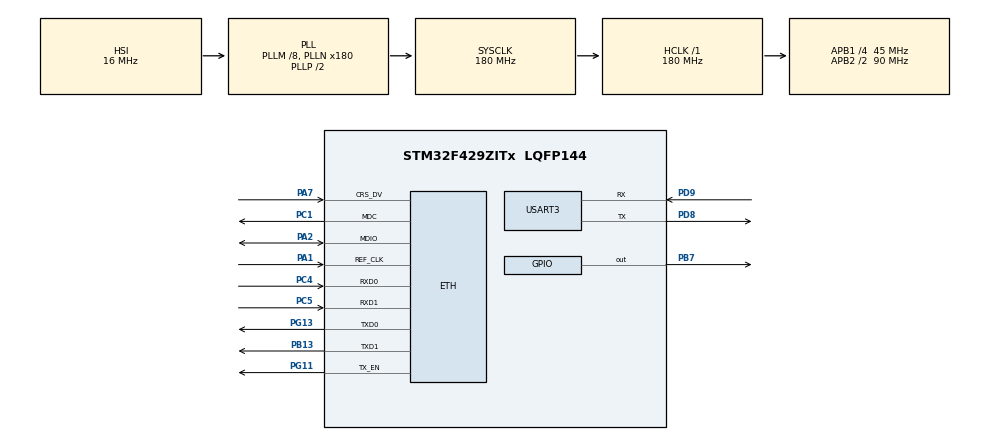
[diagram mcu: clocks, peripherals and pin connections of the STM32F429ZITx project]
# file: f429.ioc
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ETH.MediaInterface=HAL_ETH_RMII_MODE
FREERTOS.Tasks01=defaultTask,0,1024,StartDefaultTask,Default,NULL,Dynamic,NULL,NULL
FREERTOS.configTOTAL_HEAP_SIZE=131072
FREERTOS.configUSE_NEWLIB_REENTRANT=1
LWIP.BSP.number=1
LWIP.DHCP_DEBUG=LWIP_DBG_OFF
LWIP.LWIP_HTTPD=1
LWIP.LWIP_HTTPD_DYNAMIC_HEADERS=1
LWIP.LWIP_HTTPD_SSI_BY_FILE_EXTENSION=0
LWIP.LWIP_NETIF_STATUS_CALLBACK=1
LWIP.MEMP_NUM_PBUF=32
LWIP.MEMP_NUM_RAW_PCB=8
LWIP.MEMP_NUM_TCP_PCB=10
LWIP.MEM_SIZE=16384
LWIP.PBUF_POOL_SIZE=32
LWIP.Version=v2.1.2_Cube
LWIP0.BSP.STBoard=false
LWIP0.BSP.api=BSP_COMPONENT_DRIVER
LWIP0.BSP.component=LAN8742
LWIP0.BSP.instance=LAN8742
LWIP0.BSP.name=Driver_PHY
LWIP0.BSP.semaphore=S_LAN8742
LWIP0.BSP.solution=LAN8742
Mcu.Family=STM32F4
Mcu.Name=STM32F429ZITx
Mcu.Package=LQFP144
NVIC.ETH_IRQn=true\:5\:0\:false\:false\:true\:true\:true\:true\:true
NVIC.PriorityGroup=NVIC_PRIORITYGROUP_4
PA1.Mode=RMII
PA1.Signal=ETH_REF_CLK
PA2.Mode=RMII
PA2.Signal=ETH_MDIO
PA7.Mode=RMII
PA7.Signal=ETH_CRS_DV
PB13.Mode=RMII
PB13.Signal=ETH_TXD1
PB7.Signal=GPIO_Output
PC1.Mode=RMII
PC1.Signal=ETH_MDC
PC4.Mode=RMII
PC4.Signal=ETH_RXD0
PC5.Mode=RMII
PC5.Signal=ETH_RXD1
PD8.Mode=Asynchronous
PD8.Signal=USART3_TX
PD9.Mode=Asynchronous
PD9.Signal=USART3_RX
PG11.Mode=RMII
PG11.Signal=ETH_TX_EN
PG13.Mode=RMII
PG13.Signal=ETH_TXD0
ProjectManager.HeapSize=0x200
ProjectManager.StackSize=0x400
ProjectManager.TargetToolchain=STM32CubeIDE
RCC.48MHZClocksFreq_Value=90000000
RCC.AHBFreq_Value=180000000
RCC.APB1CLKDivider=RCC_HCLK_DIV4
RCC.APB1Freq_Value=45000000
RCC.APB1TimFreq_Value=90000000
RCC.APB2CLKDivider=RCC_HCLK_DIV2
RCC.APB2Freq_Value=90000000
RCC.APB2TimFreq_Value=180000000
RCC.CortexFreq_Value=180000000
RCC.HCLKFreq_Value=180000000
RCC.HSE_VALUE=25000000
RCC.HSI_VALUE=16000000
RCC.LSE_VALUE=32768
RCC.PLLM=8
RCC.PLLN=180
RCC.SYSCLKFreq_VALUE=180000000
RCC.SYSCLKSource=RCC_SYSCLKSOURCE_PLLCLK
RCC.VCOOutputFreq_Value=360000000
USART3.VirtualMode=VM_ASYNC
VP_FREERTOS_VS_CMSIS_V1.Mode=CMSIS_V1
VP_LWIP_VS_Enabled.Mode=Enabled
board=custom

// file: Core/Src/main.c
/* USER CODE BEGIN Header */
/**
  ******************************************************************************
  * @file           : main.c
  * @brief          : Main program body
  ******************************************************************************
  * @attention
  *
  * Copyright (c) 2022 STMicroelectronics.
  * All rights reserved.
  *
  * This software is licensed under terms that can be found in the LICENSE file
  * in the root directory of this software component.
  * If no LICENSE file comes with this software, it is provided AS-IS.
  *
  ******************************************************************************
  */
/* USER CODE END Header */
#include "main.h"
#include "cmsis_os.h"
#include "lwip.h"

UART_HandleTypeDef huart3;

osThreadId defaultTaskHandle;

void SystemClock_Config(void);
static void MX_GPIO_Init(void);
static void MX_USART3_UART_Init(void);
void StartDefaultTask(void const * argument);

int main(void)
{

  /* MCU Configuration--------------------------------------------------------*/

  /* Reset of all peripherals, Initializes the Flash interface and the Systick. */
  HAL_Init();

  /* Configure the system clock */
  SystemClock_Config();

  /* Initialize all configured peripherals */
  MX_GPIO_Init();
  MX_USART3_UART_Init();
  /* USER CODE BEGIN 2 */
//  for(;;) { HAL_Delay(250); HAL_GPIO_TogglePin(GPIOB, GPIO_PIN_7); }
  /* USER CODE END 2 */

  /* Create the thread(s) */
  /* definition and creation of defaultTask */
  osThreadDef(defaultTask, StartDefaultTask, osPriorityNormal, 0, 1024);
  defaultTaskHandle = osThreadCreate(osThread(defaultTask), NULL);

  /* Start scheduler */
  osKernelStart();

  /* We should never get here as control is now taken by the scheduler */
  /* Infinite loop */
  while (1)
  {

  }
}

void SystemClock_Config(void)
{
  RCC_OscInitTypeDef RCC_OscInitStruct = {0};
  RCC_ClkInitTypeDef RCC_ClkInitStruct = {0};

  /** Configure the main internal regulator output voltage
  */
  __HAL_RCC_PWR_CLK_ENABLE();
  __HAL_PWR_VOLTAGESCALING_CONFIG(PWR_REGULATOR_VOLTAGE_SCALE1);

  /** Initializes the RCC Oscillators according to the specified parameters
  * in the RCC_OscInitTypeDef structure.
  */
  RCC_OscInitStruct.OscillatorType = RCC_OSCILLATORTYPE_HSI;
  RCC_OscInitStruct.HSIState = RCC_HSI_ON;
  RCC_OscInitStruct.HSICalibrationValue = RCC_HSICALIBRATION_DEFAULT;
  RCC_OscInitStruct.PLL.PLLState = RCC_PLL_ON;
  RCC_OscInitStruct.PLL.PLLSource = RCC_PLLSOURCE_HSI;
  RCC_OscInitStruct.PLL.PLLM = 8;
  RCC_OscInitStruct.PLL.PLLN = 180;
  RCC_OscInitStruct.PLL.PLLP = RCC_PLLP_DIV2;
  RCC_OscInitStruct.PLL.PLLQ = 4;
  if (HAL_RCC_OscConfig(&RCC_OscInitStruct) != HAL_OK)
  {
    Error_Handler();
  }

  /** Activate the Over-Drive mode
  */
  if (HAL_PWREx_EnableOverDrive() != HAL_OK)
  {
    Error_Handler();
  }

  /** Initializes the CPU, AHB and APB buses clocks
  */
  RCC_ClkInitStruct.ClockType = RCC_CLOCKTYPE_HCLK|RCC_CLOCKTYPE_SYSCLK
                              |RCC_CLOCKTYPE_PCLK1|RCC_CLOCKTYPE_PCLK2;
  RCC_ClkInitStruct.SYSCLKSource = RCC_SYSCLKSOURCE_PLLCLK;
  RCC_ClkInitStruct.AHBCLKDivider = RCC_SYSCLK_DIV1;
  RCC_ClkInitStruct.APB1CLKDivider = RCC_HCLK_DIV4;
  RCC_ClkInitStruct.APB2CLKDivider = RCC_HCLK_DIV2;

  if (HAL_RCC_ClockConfig(&RCC_ClkInitStruct, FLASH_LATENCY_5) != HAL_OK)
  {
    Error_Handler();
  }
}

static void MX_USART3_UART_Init(void)
{

  huart3.Instance = USART3;
  huart3.Init.BaudRate = 115200;
  huart3.Init.WordLength = UART_WORDLENGTH_8B;
  huart3.Init.StopBits = UART_STOPBITS_1;
  huart3.Init.Parity = UART_PARITY_NONE;
  huart3.Init.Mode = UART_MODE_TX_RX;
  huart3.Init.HwFlowCtl = UART_HWCONTROL_NONE;
  huart3.Init.OverSampling = UART_OVERSAMPLING_16;
  if (HAL_UART_Init(&huart3) != HAL_OK)
  {
    Error_Handler();
  }

}

static void MX_GPIO_Init(void)
{
  GPIO_InitTypeDef GPIO_InitStruct = {0};

  /* GPIO Ports Clock Enable */
  __HAL_RCC_GPIOC_CLK_ENABLE();
  __HAL_RCC_GPIOA_CLK_ENABLE();
  __HAL_RCC_GPIOB_CLK_ENABLE();
  __HAL_RCC_GPIOD_CLK_ENABLE();
  __HAL_RCC_GPIOG_CLK_ENABLE();

  /*Configure GPIO pin Output Level */
  HAL_GPIO_WritePin(GPIOB, GPIO_PIN_7, GPIO_PIN_RESET);

  /*Configure GPIO pin : PB7 */
  GPIO_InitStruct.Pin = GPIO_PIN_7;
  GPIO_InitStruct.Mode = GPIO_MODE_OUTPUT_PP;
  GPIO_InitStruct.Pull = GPIO_NOPULL;
  GPIO_InitStruct.Speed = GPIO_SPEED_FREQ_LOW;
  HAL_GPIO_Init(GPIOB, &GPIO_InitStruct);

}

/* USER CODE BEGIN 4 */
int ip_ready = 0;
/* USER CODE END 4 */

void StartDefaultTask(void const * argument)
{
  /* init code for LWIP */
  MX_LWIP_Init();
  /* USER CODE BEGIN 5 */
  /* Infinite loop */
  extern struct netif gnetif;
  extern void httpd_init(void);
  while (gnetif.ip_addr.addr == 0) HAL_Delay(100);
  httpd_init();

  for(;;) {
	  HAL_Delay(1250); HAL_GPIO_TogglePin(GPIOB, GPIO_PIN_7);
    printf("hi, time %lu, ram: %lu, lwm: %lu\r\n", HAL_GetTick(),
          xPortGetFreeHeapSize(),
          xPortGetMinimumEverFreeHeapSize());
  }
  /* USER CODE END 5 */
}

void Error_Handler(void)
{
  __disable_irq();
  while (1)
  {
  }
}
